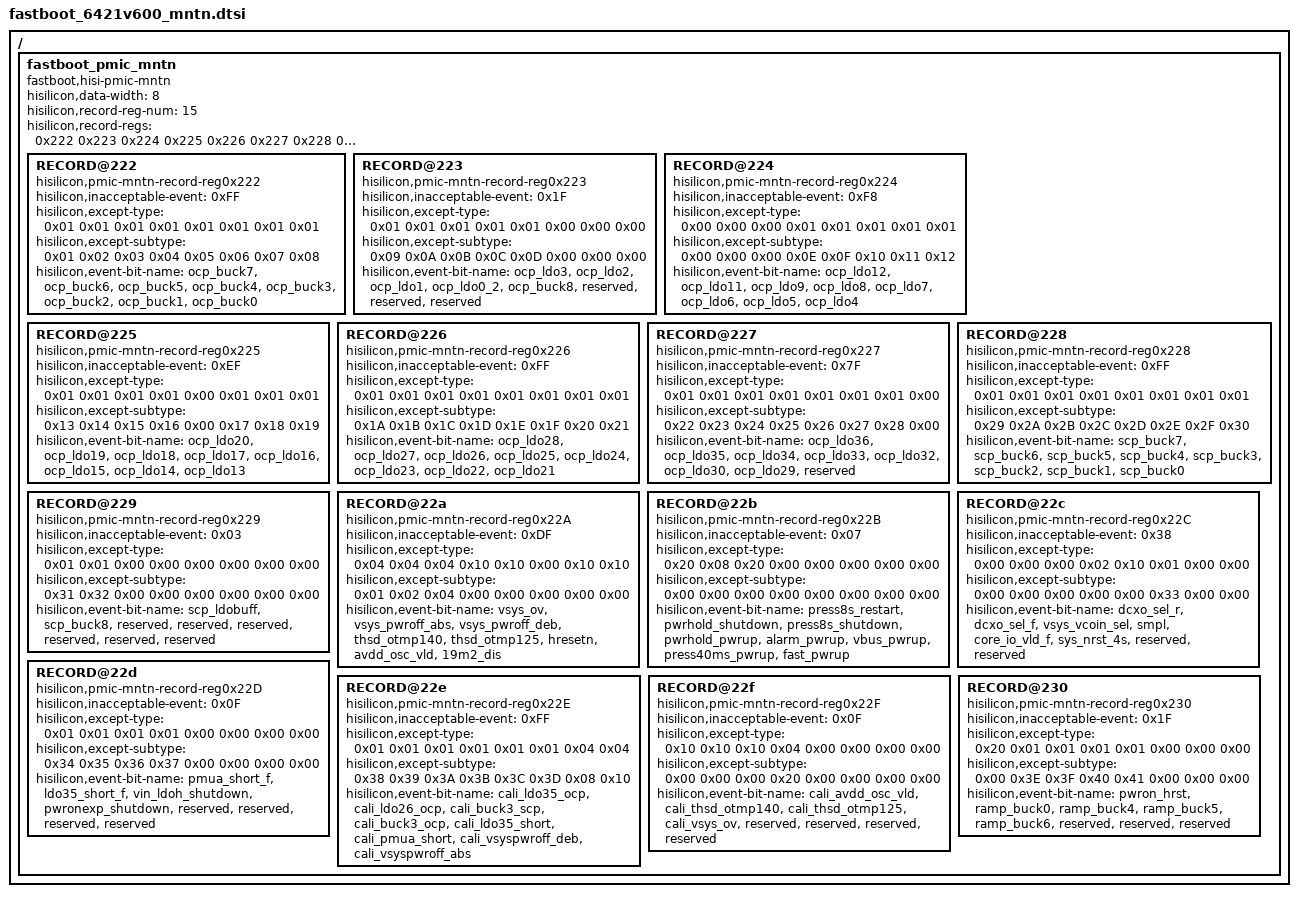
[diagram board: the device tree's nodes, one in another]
/******************************************************************************

                  版权所有 (C), 2001-2011, 华为技术有限公司

 ******************************************************************************

  This is an AUTO GENERATED file ! DON'T MODIFY MANUAL!
  文 件 名   : %(filename)s
  生成日期   : %(year)d年%(month)d月%(day)d日

******************************************************************************/

/ {
	fastboot_pmic_mntn: fastboot_pmic_mntn {
		compatible = "fastboot,hisi-pmic-mntn";
		hisilicon,data-width = <8>;
		hisilicon,record-reg-num = <15>;
		hisilicon,record-regs = <0x222 0x223 0x224 0x225 0x226 0x227 0x228 0x229 0x22A 0x22B 0x22C 0x22D 0x22E 0x22F 0x230>;

		RECORD@222 {
			compatible = "hisilicon,pmic-mntn-record-reg0x222";
			hisilicon,inacceptable-event = <0xFF>;
			/* every event must be signed a except type, and every except type is signed for a bit */
			/* 0x00:null; 0x01:except; 0x02:smpl; 0x04:scharger; 0x08:pwrhold; 0x10:pwroff_except; 0x20:pwroff_no_except */
			hisilicon,except-type = <0x01 0x01 0x01 0x01 0x01 0x01 0x01 0x01>;
			hisilicon,except-subtype = <0x01 0x02 0x03 0x04 0x05 0x06 0x07 0x08>;
			/* max len of per event-bit-name is 20 bytes */
			hisilicon,event-bit-name = "ocp_buck7","ocp_buck6","ocp_buck5","ocp_buck4","ocp_buck3","ocp_buck2","ocp_buck1","ocp_buck0";
		};

		RECORD@223 {
			compatible = "hisilicon,pmic-mntn-record-reg0x223";
			hisilicon,inacceptable-event = <0x1F>;
			hisilicon,except-type = <0x01 0x01 0x01 0x01 0x01 0x00 0x00 0x00>;
			hisilicon,except-subtype = <0x09 0x0A 0x0B 0x0C 0x0D 0x00 0x00 0x00>;
			hisilicon,event-bit-name = "ocp_ldo3","ocp_ldo2","ocp_ldo1","ocp_ldo0_2","ocp_buck8","reserved","reserved","reserved";
		};

		RECORD@224 {
			compatible = "hisilicon,pmic-mntn-record-reg0x224";
			hisilicon,inacceptable-event = <0xF8>;
			hisilicon,except-type = <0x00 0x00 0x00 0x01 0x01 0x01 0x01 0x01>;
			hisilicon,except-subtype = <0x00 0x00 0x00 0x0E 0x0F 0x10 0x11 0x12>;
			hisilicon,event-bit-name = "ocp_ldo12","ocp_ldo11","ocp_ldo9","ocp_ldo8","ocp_ldo7","ocp_ldo6","ocp_ldo5","ocp_ldo4";
		};

		RECORD@225 {
			compatible = "hisilicon,pmic-mntn-record-reg0x225";
			hisilicon,inacceptable-event = <0xEF>;
			hisilicon,except-type = <0x01 0x01 0x01 0x01 0x00 0x01 0x01 0x01>;
			hisilicon,except-subtype = <0x13 0x14 0x15 0x16 0x00 0x17 0x18 0x19>;
			hisilicon,event-bit-name = "ocp_ldo20","ocp_ldo19","ocp_ldo18","ocp_ldo17","ocp_ldo16","ocp_ldo15","ocp_ldo14","ocp_ldo13";
		};

		RECORD@226 {
			compatible = "hisilicon,pmic-mntn-record-reg0x226";
			hisilicon,inacceptable-event = <0xFF>;
			hisilicon,except-type = <0x01 0x01 0x01 0x01 0x01 0x01 0x01 0x01>;
			hisilicon,except-subtype = <0x1A 0x1B 0x1C 0x1D 0x1E 0x1F 0x20 0x21>;
			hisilicon,event-bit-name = "ocp_ldo28","ocp_ldo27","ocp_ldo26","ocp_ldo25","ocp_ldo24","ocp_ldo23","ocp_ldo22","ocp_ldo21";
		};

		RECORD@227 {
			compatible = "hisilicon,pmic-mntn-record-reg0x227";
			hisilicon,inacceptable-event = <0x7F>;
			hisilicon,except-type = <0x01 0x01 0x01 0x01 0x01 0x01 0x01 0x00>;
			hisilicon,except-subtype = <0x22 0x23 0x24 0x25 0x26 0x27 0x28 0x00>;
			hisilicon,event-bit-name = "ocp_ldo36","ocp_ldo35","ocp_ldo34","ocp_ldo33","ocp_ldo32","ocp_ldo30","ocp_ldo29","reserved";
		};

		RECORD@228 {
			compatible = "hisilicon,pmic-mntn-record-reg0x228";
			hisilicon,inacceptable-event = <0xFF>;
			hisilicon,except-type = <0x01 0x01 0x01 0x01 0x01 0x01 0x01 0x01>;
			hisilicon,except-subtype = <0x29 0x2A 0x2B 0x2C 0x2D 0x2E 0x2F 0x30>;
			hisilicon,event-bit-name = "scp_buck7","scp_buck6","scp_buck5","scp_buck4","scp_buck3","scp_buck2","scp_buck1","scp_buck0";
		};

		RECORD@229 {
			compatible = "hisilicon,pmic-mntn-record-reg0x229";
			hisilicon,inacceptable-event = <0x03>;
			hisilicon,except-type = <0x01 0x01 0x00 0x00 0x00 0x00 0x00 0x00>;
			hisilicon,except-subtype = <0x31 0x32 0x00 0x00 0x00 0x00 0x00 0x00>;
			hisilicon,event-bit-name = "scp_ldobuff","scp_buck8","reserved","reserved","reserved","reserved","reserved","reserved";
		};

		RECORD@22a {
			compatible = "hisilicon,pmic-mntn-record-reg0x22A";
			hisilicon,inacceptable-event = <0xDF>;
			hisilicon,except-type = <0x04 0x04 0x04 0x10 0x10 0x00 0x10 0x10>;
			hisilicon,except-subtype = <0x01 0x02 0x04 0x00 0x00 0x00 0x00 0x00>;
			hisilicon,event-bit-name = "vsys_ov","vsys_pwroff_abs","vsys_pwroff_deb","thsd_otmp140","thsd_otmp125","hresetn","avdd_osc_vld","19m2_dis";
		};

		RECORD@22b {
			compatible = "hisilicon,pmic-mntn-record-reg0x22B";
			hisilicon,inacceptable-event = <0x07>;
			hisilicon,except-type = <0x20 0x08 0x20 0x00 0x00 0x00 0x00 0x00>;
			hisilicon,except-subtype = <0x00 0x00 0x00 0x00 0x00 0x00 0x00 0x00>;
			hisilicon,event-bit-name = "press8s_restart","pwrhold_shutdown","press8s_shutdown","pwrhold_pwrup","alarm_pwrup","vbus_pwrup","press40ms_pwrup","fast_pwrup";
		};

		RECORD@22c {
			compatible = "hisilicon,pmic-mntn-record-reg0x22C";
			hisilicon,inacceptable-event = <0x38>;
			hisilicon,except-type = <0x00 0x00 0x00 0x02 0x10 0x01 0x00 0x00>;
			hisilicon,except-subtype = <0x00 0x00 0x00 0x00 0x00 0x33 0x00 0x00>;
			hisilicon,event-bit-name = "dcxo_sel_r","dcxo_sel_f","vsys_vcoin_sel","smpl","core_io_vld_f","sys_nrst_4s","reserved","reserved";
		};

		RECORD@22d {
			compatible = "hisilicon,pmic-mntn-record-reg0x22D";
			hisilicon,inacceptable-event = <0x0F>;
			hisilicon,except-type = <0x01 0x01 0x01 0x01 0x00 0x00 0x00 0x00>;
			hisilicon,except-subtype = <0x34 0x35 0x36 0x37 0x00 0x00 0x00 0x00>;
			hisilicon,event-bit-name = "pmua_short_f","ldo35_short_f","vin_ldoh_shutdown","pwronexp_shutdown","reserved","reserved","reserved","reserved";
		};

		RECORD@22e {
			compatible = "hisilicon,pmic-mntn-record-reg0x22E";
			hisilicon,inacceptable-event = <0xFF>;
			hisilicon,except-type = <0x01 0x01 0x01 0x01 0x01 0x01 0x04 0x04>;
			hisilicon,except-subtype = <0x38 0x39 0x3A 0x3B 0x3C 0x3D 0x08 0x10>;
			hisilicon,event-bit-name = "cali_ldo35_ocp","cali_ldo26_ocp","cali_buck3_scp","cali_buck3_ocp","cali_ldo35_short","cali_pmua_short","cali_vsyspwroff_deb","cali_vsyspwroff_abs";
		};

		RECORD@22f {
			compatible = "hisilicon,pmic-mntn-record-reg0x22F";
			hisilicon,inacceptable-event = <0x0F>;
			hisilicon,except-type = <0x10 0x10 0x10 0x04 0x00 0x00 0x00 0x00>;
			hisilicon,except-subtype = <0x00 0x00 0x00 0x20 0x00 0x00 0x00 0x00>;
			hisilicon,event-bit-name = "cali_avdd_osc_vld","cali_thsd_otmp140","cali_thsd_otmp125","cali_vsys_ov","reserved","reserved","reserved","reserved";
		};

		RECORD@230 {
			compatible = "hisilicon,pmic-mntn-record-reg0x230";
			hisilicon,inacceptable-event = <0x1F>;
			hisilicon,except-type = <0x20 0x01 0x01 0x01 0x01 0x00 0x00 0x00>;
			hisilicon,except-subtype = <0x00 0x3E 0x3F 0x40 0x41 0x00 0x00 0x00>;
			hisilicon,event-bit-name = "pwron_hrst","ramp_buck0","ramp_buck4","ramp_buck5","ramp_buck6","reserved","reserved","reserved";
		};
	};
};
